# DPHY_TX0 register map
Vendor: Texas Instruments
Peripheral module from a debugger description file (folder J7ES).
Registers are 32-bit, read-write, reset 0x0 unless marked. A register's access mark holds for its fields unless they carry their own. Offsets are as the file gives them; lines under a group give offsets from that group; [hi:lo] are bit positions; {n}, {i} and the like mark numbered series; 'fields as' and 'values as' point back to an identical list; <NAME> marks a mode.

## DPHY_TX0
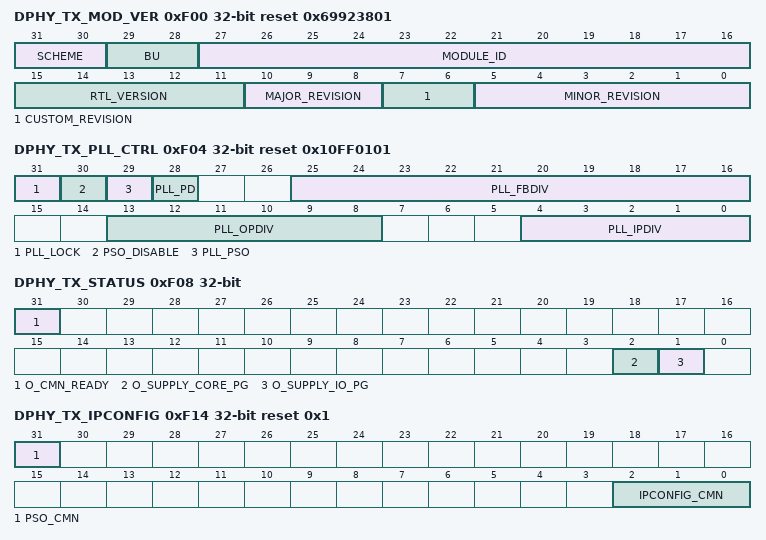
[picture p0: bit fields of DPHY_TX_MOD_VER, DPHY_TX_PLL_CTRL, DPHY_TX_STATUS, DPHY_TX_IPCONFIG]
0xF00 DPHY_TX_MOD_VER ro reset 0x69923801 — The Module and Version Register identifies the module identifier and revision of the WIZ16B8M4CDT module.
  [31:30] SCHEME — Module Scheme
  [29:28] BU — Module Business Unit
  [27:16] MODULE_ID — WIZ16B8M4CDT module ID.
  [15:11] RTL_VERSION
  [10:8] MAJOR_REVISION
  [7:6] CUSTOM_REVISION
  [5:0] MINOR_REVISION
0xF04 DPHY_TX_PLL_CTRL access per field reset 0x10FF0101 — Sets the PLL info.
  [31] PLL_LOCK ro — Signal to indicate that PLL has got locked. 1: PLL locked to required frequency 0: PLL not yet locked
  [30] PSO_DISABLE rw — Disables the ability to switch off the analog switched power islands in the lane when in the ultra-low power state
  [29] PLL_PSO rw — Power Shut Off signal for PLL 1: PLL shutoff 0: PLL power ON
  [28] PLL_PD rw — Power down signal for PLL (Does not switch off the PLL supply) 1: PLL is powered down 0: PLL is active
  [25:16] PLL_FBDIV rw — DPHY TX PLL VCO Feedback Divider ratio. Feedback divider value = ROUND ((Data Rate * 2 * pll_opdiv * pll_ipdiv) / PLL reference clock frequency)
  [13:8] PLL_OPDIV rw — DPHY TX PLL OUTCLK Divider ratio.&lt;BR&gt; 6'h 01: Div by 1, 2.5 Gbps - 1.25 Gbps&lt;BR&gt; 6'h 02: Div by 2, 1.24 Gbps - 630 Mbps&lt;BR&gt; 6'h 04: Div by 4, 620 Mbps - 320 Mbps&lt;BR&gt; 6'h 08: Div by 8, 310 Mbps - 160 Mbps&lt;BR&gt; 6'h 10: Div by 16, 150 Mbps - 80 Mbps
  [4:0] PLL_IPDIV rw — DPHY TX PLL REFCLK Input Divider ratio.&lt;BR&gt; 5'h 01: Div by 1, 9.6 MHz - &lt;19.2 MHz&lt;BR&gt; 5'h 02: Div by 2, 19.2 MHz - &lt;38.4 MHz&lt;BR&gt; 5'h 04: Div by 4, 38.4 MHz - &lt; 76.8 MHz&lt;BR&gt; 5'h 08: Div by 8, 76.8 MHz - &lt; 150 MHz
0xF08 DPHY_TX_STATUS ro — The register reports of the DPHYTS sub module.
  [31] O_CMN_READY — System Should check this during Power up Initialisation
  [2] O_SUPPLY_CORE_PG — The indicates the core supply is good.
  [1] O_SUPPLY_IO_PG — The indicates the IO supply is good.
0xF0C DPHY_TX_RST_CTRL — Sets the RST info.
  [31] LANE_RSTB_CMN — DPHY System Reset for Common Module - required to be released after APB register programming See DPHY PMA specification for details of DPHY power up sequence
0xF10 DPHY_TX_PSM_FREQ reset 0x1 — The PSM Frequency register configures the so that it knows hoe fast the PSM clock is.
  [7:0] PSM_CLOCK_FREQ — Static value based on System PSM clock frequency. The signal must be driven with a value such that the internal psm frequency of the divided psm clock is 1 MHz
0xF14 DPHY_TX_IPCONFIG reset 0x1 — IP Config
  [31] PSO_CMN — Power Shutoff signal for CMN 1: CMN is power OFF 0: CMN is power ON
  [2:0] IPCONFIG_CMN — This signal decides which clock lane acts as master clock lane to all data lanes. Needed only for RXIP. Bit[2]: Reserved CASE {Bit[1],Bit[0]}: 00: Left RX clk lane provides clock to all left and right data lanes. 01: Left RX clk lane provides clock to all right data lanes, Right RX clk lane provides clock to all left data lanes. 10: Right RX clk lane provides clock to all right data lanes, Left RX clk lane provides clock to all left data lanes. 11: Right RX clk lane provides clock to all left and right data lanes.
0xFF8 DPHY_TX_PLLRES — The PLL Reserved register is not being used currently
  [7:0] PLLREFSEL_CMN — PLL frequency range. This signal is not being used currently. Should be 8'd0
0xFFC DPHY_TX_DIAG_TEST — The Diagnostic Test Register allows the system to validate the read and write of all data bits.
  [31:0] DIAG_REG — Diagnostic register.
